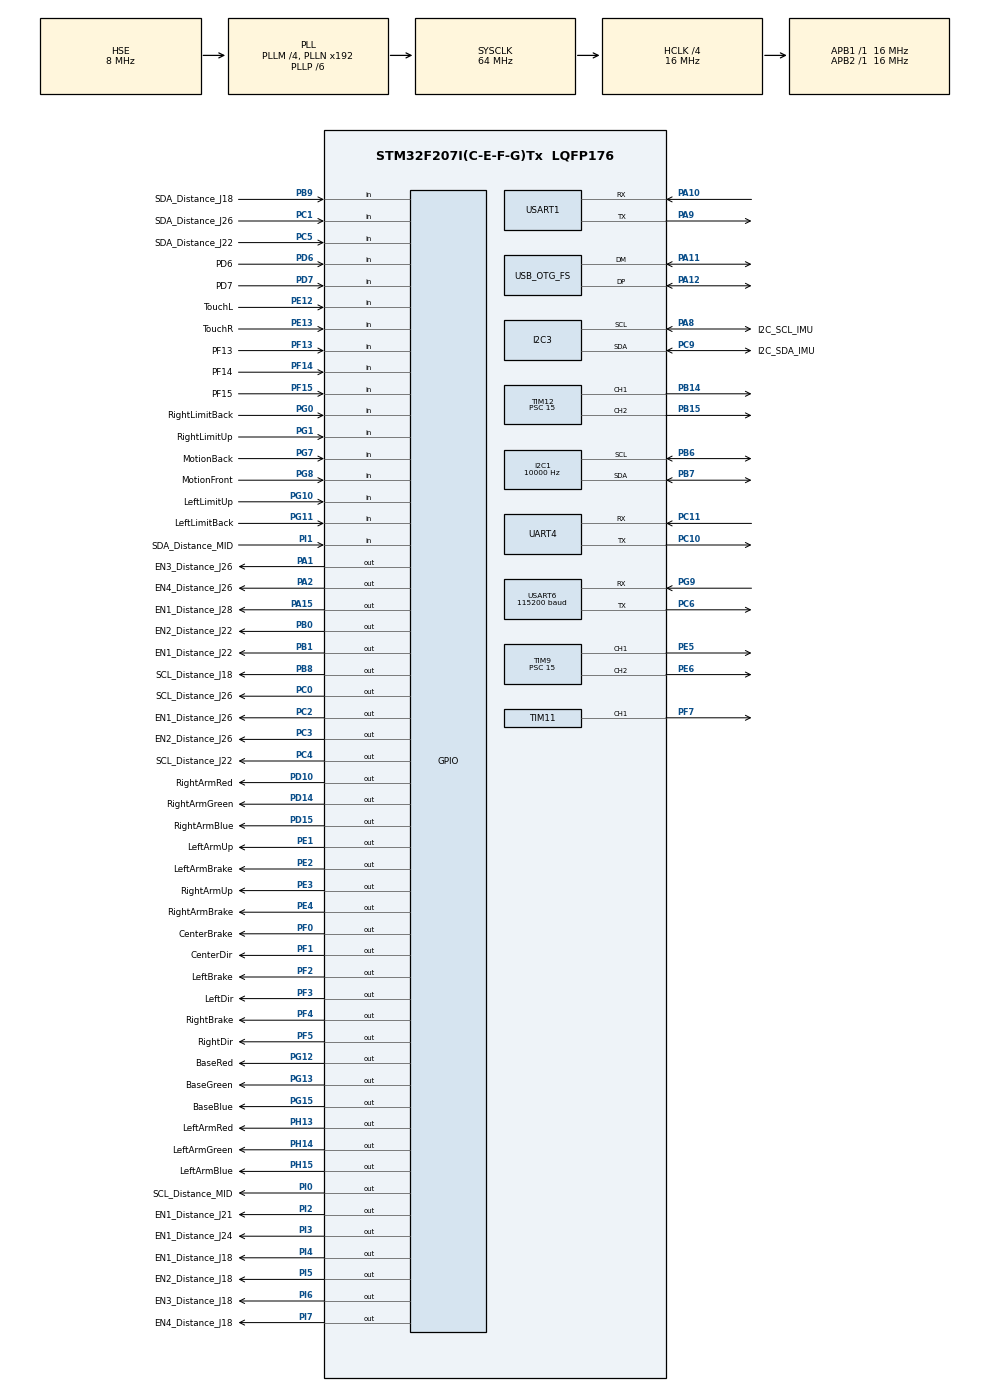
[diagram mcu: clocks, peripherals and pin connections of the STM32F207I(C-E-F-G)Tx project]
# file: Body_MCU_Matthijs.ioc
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Dma.Request0=USART6_RX
Dma.Request1=USART1_RX
Dma.Request2=USART1_TX
Dma.USART1_RX.1.Direction=DMA_PERIPH_TO_MEMORY
Dma.USART1_RX.1.FIFOMode=DMA_FIFOMODE_DISABLE
Dma.USART1_RX.1.Instance=DMA2_Stream2
Dma.USART1_RX.1.MemDataAlignment=DMA_MDATAALIGN_BYTE
Dma.USART1_RX.1.MemInc=DMA_MINC_ENABLE
Dma.USART1_RX.1.Mode=DMA_NORMAL
Dma.USART1_RX.1.PeriphDataAlignment=DMA_PDATAALIGN_BYTE
Dma.USART1_RX.1.PeriphInc=DMA_PINC_DISABLE
Dma.USART1_RX.1.Priority=DMA_PRIORITY_LOW
Dma.USART1_TX.2.Direction=DMA_MEMORY_TO_PERIPH
Dma.USART1_TX.2.FIFOMode=DMA_FIFOMODE_DISABLE
Dma.USART1_TX.2.Instance=DMA2_Stream7
Dma.USART1_TX.2.MemDataAlignment=DMA_MDATAALIGN_BYTE
Dma.USART1_TX.2.MemInc=DMA_MINC_ENABLE
Dma.USART1_TX.2.Mode=DMA_NORMAL
Dma.USART1_TX.2.PeriphDataAlignment=DMA_PDATAALIGN_BYTE
Dma.USART1_TX.2.PeriphInc=DMA_PINC_DISABLE
Dma.USART1_TX.2.Priority=DMA_PRIORITY_LOW
Dma.USART6_RX.0.Direction=DMA_PERIPH_TO_MEMORY
Dma.USART6_RX.0.FIFOMode=DMA_FIFOMODE_DISABLE
Dma.USART6_RX.0.Instance=DMA2_Stream1
Dma.USART6_RX.0.MemDataAlignment=DMA_MDATAALIGN_BYTE
Dma.USART6_RX.0.MemInc=DMA_MINC_ENABLE
Dma.USART6_RX.0.Mode=DMA_NORMAL
Dma.USART6_RX.0.PeriphDataAlignment=DMA_PDATAALIGN_BYTE
Dma.USART6_RX.0.PeriphInc=DMA_PINC_DISABLE
Dma.USART6_RX.0.Priority=DMA_PRIORITY_LOW
I2C1.ClockSpeed=10000
Mcu.Family=STM32F2
Mcu.Name=STM32F207I(C-E-F-G)Tx
Mcu.Package=LQFP176
NVIC.DMA2_Stream1_IRQn=true\:0\:0\:false\:false\:true\:false\:true\:true
NVIC.DMA2_Stream2_IRQn=true\:0\:0\:false\:false\:true\:false\:true\:true
NVIC.DMA2_Stream7_IRQn=true\:0\:0\:false\:false\:true\:false\:true\:true
NVIC.I2C3_EV_IRQn=true\:0\:0\:false\:false\:true\:true\:true\:true
NVIC.OTG_FS_IRQn=true\:0\:0\:false\:false\:true\:false\:true\:true
NVIC.PriorityGroup=NVIC_PRIORITYGROUP_4
NVIC.TIM8_TRG_COM_TIM14_IRQn=true\:0\:0\:false\:false\:true\:true\:true\:true
NVIC.UART4_IRQn=true\:0\:0\:false\:false\:true\:true\:true\:true
NVIC.USART1_IRQn=true\:0\:0\:false\:false\:true\:true\:true\:true
NVIC.USART6_IRQn=true\:0\:0\:false\:false\:true\:true\:true\:true
PA1.GPIO_Label=EN3_Distance_J26
PA1.GPIO_PuPd=GPIO_PULLDOWN
PA1.GPIO_Speed=GPIO_SPEED_FREQ_HIGH
PA1.Signal=GPIO_Output
PA10.Mode=Asynchronous
PA10.Signal=USART1_RX
PA11.Mode=Device_Only
PA11.Signal=USB_OTG_FS_DM
PA12.Mode=Device_Only
PA12.Signal=USB_OTG_FS_DP
PA13.Mode=Serial_Wire
PA13.Signal=SYS_JTMS-SWDIO
PA14.Mode=Serial_Wire
PA14.Signal=SYS_JTCK-SWCLK
PA15.GPIO_Label=EN1_Distance_J28
PA15.GPIO_PuPd=GPIO_PULLDOWN
PA15.GPIO_Speed=GPIO_SPEED_FREQ_HIGH
PA15.Signal=GPIO_Output
PA2.GPIO_Label=EN4_Distance_J26
PA2.GPIO_PuPd=GPIO_PULLDOWN
PA2.GPIO_Speed=GPIO_SPEED_FREQ_HIGH
PA2.Signal=GPIO_Output
PA8.GPIO_Label=I2C_SCL_IMU
PA8.GPIO_Pu=GPIO_PULLUP
PA8.Mode=I2C
PA8.Signal=I2C3_SCL
PA9.Mode=Asynchronous
PA9.Signal=USART1_TX
PB0.GPIO_Label=EN2_Distance_J22
PB0.GPIO_PuPd=GPIO_PULLDOWN
PB0.GPIO_Speed=GPIO_SPEED_FREQ_HIGH
PB0.Signal=GPIO_Output
PB1.GPIO_Label=EN1_Distance_J22
PB1.GPIO_PuPd=GPIO_PULLDOWN
PB1.GPIO_Speed=GPIO_SPEED_FREQ_HIGH
PB1.Signal=GPIO_Output
PB14.GPIO_PuPd=GPIO_PULLDOWN
PB14.Signal=S_TIM12_CH1
PB15.Signal=S_TIM12_CH2
PB6.GPIO_Pu=GPIO_PULLUP
PB6.Mode=I2C
PB6.Signal=I2C1_SCL
PB7.GPIO_Pu=GPIO_PULLUP
PB7.Mode=I2C
PB7.Signal=I2C1_SDA
PB8.GPIO_Label=SCL_Distance_J18
PB8.GPIO_Speed=GPIO_SPEED_FREQ_VERY_HIGH
PB8.Signal=GPIO_Output
PB9.GPIO_Label=SDA_Distance_J18
PB9.GPIO_PuPd=GPIO_PULLUP
PB9.Signal=GPIO_Input
PC0.GPIO_Label=SCL_Distance_J26
PC0.GPIO_PuPd=GPIO_NOPULL
PC0.GPIO_Speed=GPIO_SPEED_FREQ_VERY_HIGH
PC0.Signal=GPIO_Output
PC1.GPIO_Label=SDA_Distance_J26
PC1.GPIO_PuPd=GPIO_PULLUP
PC1.Signal=GPIO_Input
PC10.Mode=Asynchronous
PC10.Signal=UART4_TX
PC11.Mode=Asynchronous
PC11.Signal=UART4_RX
PC2.GPIO_Label=EN1_Distance_J26
PC2.GPIO_PuPd=GPIO_PULLDOWN
PC2.GPIO_Speed=GPIO_SPEED_FREQ_HIGH
PC2.Signal=GPIO_Output
PC3.GPIO_Label=EN2_Distance_J26
PC3.GPIO_PuPd=GPIO_PULLDOWN
PC3.GPIO_Speed=GPIO_SPEED_FREQ_HIGH
PC3.Signal=GPIO_Output
PC4.GPIO_Label=SCL_Distance_J22
PC4.GPIO_Speed=GPIO_SPEED_FREQ_VERY_HIGH
PC4.Signal=GPIO_Output
PC5.GPIO_Label=SDA_Distance_J22
PC5.GPIO_PuPd=GPIO_PULLUP
PC5.Signal=GPIO_Input
PC6.Mode=Asynchronous
PC6.Signal=USART6_TX
PC9.GPIO_Label=I2C_SDA_IMU
PC9.GPIO_Pu=GPIO_PULLUP
PC9.Mode=I2C
PC9.Signal=I2C3_SDA
PD10.GPIO_Label=RightArmRed
PD10.GPIO_PuPd=GPIO_PULLDOWN
PD10.Signal=GPIO_Output
PD14.GPIO_Label=RightArmGreen
PD14.GPIO_PuPd=GPIO_PULLDOWN
PD14.Signal=GPIO_Output
PD15.GPIO_Label=RightArmBlue
PD15.GPIO_PuPd=GPIO_PULLDOWN
PD15.Signal=GPIO_Output
PD6.GPIO_Label=PD6
PD6.Signal=GPIO_Input
PD7.GPIO_Label=PD7
PD7.Signal=GPIO_Input
PE1.GPIO_Label=LeftArmUp
PE1.GPIO_PuPd=GPIO_PULLDOWN
PE1.GPIO_Speed=GPIO_SPEED_FREQ_LOW
PE1.Signal=GPIO_Output
PE12.GPIO_Label=TouchL
PE12.GPIO_PuPd=GPIO_PULLUP
PE12.Signal=GPIO_Input
PE13.GPIO_Label=TouchR
PE13.GPIO_PuPd=GPIO_PULLUP
PE13.Signal=GPIO_Input
PE2.GPIO_Label=LeftArmBrake
PE2.GPIO_PuPd=GPIO_PULLDOWN
PE2.GPIO_Speed=GPIO_SPEED_FREQ_LOW
PE2.Signal=GPIO_Output
PE3.GPIO_Label=RightArmUp
PE3.GPIO_PuPd=GPIO_PULLDOWN
PE3.GPIO_Speed=GPIO_SPEED_FREQ_LOW
PE3.Signal=GPIO_Output
PE4.GPIO_Label=RightArmBrake
PE4.GPIO_PuPd=GPIO_PULLDOWN
PE4.Signal=GPIO_Output
PE5.GPIO_PuPd=GPIO_PULLDOWN
PE5.Signal=S_TIM9_CH1
PE6.GPIO_PuPd=GPIO_PULLDOWN
PE6.Signal=S_TIM9_CH2
PF0.GPIO_Label=CenterBrake
PF0.GPIO_PuPd=GPIO_PULLDOWN
PF0.Signal=GPIO_Output
PF1.GPIO_Label=CenterDir
PF1.GPIO_PuPd=GPIO_PULLDOWN
PF1.Signal=GPIO_Output
PF13.GPIO_Label=PF13
PF13.Signal=GPIO_Input
PF14.GPIO_Label=PF14
PF14.Signal=GPIO_Input
PF15.GPIO_Label=PF15
PF15.Signal=GPIO_Input
PF2.GPIO_Label=LeftBrake
PF2.GPIO_PuPd=GPIO_PULLDOWN
PF2.Signal=GPIO_Output
PF3.GPIO_Label=LeftDir
PF3.GPIO_PuPd=GPIO_PULLDOWN
PF3.Signal=GPIO_Output
PF4.GPIO_Label=RightBrake
PF4.GPIO_PuPd=GPIO_PULLDOWN
PF4.Signal=GPIO_Output
PF5.GPIO_Label=RightDir
PF5.GPIO_PuPd=GPIO_PULLDOWN
PF5.Signal=GPIO_Output
PF7.GPIO_PuPd=GPIO_PULLDOWN
PF7.GPIO_Speed=GPIO_SPEED_FREQ_LOW
PF7.Signal=S_TIM11_CH1
PG0.GPIO_Label=RightLimitBack
PG0.Signal=GPIO_Input
PG1.GPIO_Label=RightLimitUp
PG1.Signal=GPIO_Input
PG10.GPIO_Label=LeftLimitUp
PG10.Signal=GPIO_Input
PG11.GPIO_Label=LeftLimitBack
PG11.Signal=GPIO_Input
PG12.GPIO_Label=BaseRed
PG12.GPIO_PuPd=GPIO_PULLDOWN
PG12.Signal=GPIO_Output
PG13.GPIO_Label=BaseGreen
PG13.GPIO_PuPd=GPIO_PULLDOWN
PG13.Signal=GPIO_Output
PG15.GPIO_Label=BaseBlue
PG15.GPIO_PuPd=GPIO_PULLDOWN
PG15.Signal=GPIO_Output
PG7.GPIO_Label=MotionBack
PG7.Signal=GPIO_Input
PG8.GPIO_Label=MotionFront
PG8.Signal=GPIO_Input
PG9.Mode=Asynchronous
PG9.Signal=USART6_RX
PH0-OSC_IN.Mode=HSE-External-Oscillator
PH0-OSC_IN.Signal=RCC_OSC_IN
PH1-OSC_OUT.Mode=HSE-External-Oscillator
PH1-OSC_OUT.Signal=RCC_OSC_OUT
PH13.GPIO_Label=LeftArmRed
PH13.GPIO_PuPd=GPIO_PULLDOWN
PH13.Signal=GPIO_Output
PH14.GPIO_Label=LeftArmGreen
PH14.GPIO_PuPd=GPIO_PULLDOWN
PH14.Signal=GPIO_Output
PH15.GPIO_Label=LeftArmBlue
PH15.GPIO_PuPd=GPIO_PULLDOWN
PH15.Signal=GPIO_Output
PI0.GPIO_Label=SCL_Distance_MID
PI0.GPIO_Speed=GPIO_SPEED_FREQ_VERY_HIGH
PI0.Signal=GPIO_Output
PI1.GPIO_Label=SDA_Distance_MID
PI1.GPIO_PuPd=GPIO_PULLUP
PI1.Signal=GPIO_Input
PI2.GPIO_Label=EN1_Distance_J21
PI2.GPIO_PuPd=GPIO_PULLDOWN
PI2.GPIO_Speed=GPIO_SPEED_FREQ_HIGH
PI2.Signal=GPIO_Output
PI3.GPIO_Label=EN1_Distance_J24
PI3.GPIO_PuPd=GPIO_PULLDOWN
PI3.GPIO_Speed=GPIO_SPEED_FREQ_HIGH
PI3.Signal=GPIO_Output
PI4.GPIO_Label=EN1_Distance_J18
PI4.GPIO_PuPd=GPIO_PULLDOWN
PI4.GPIO_Speed=GPIO_SPEED_FREQ_HIGH
PI4.Signal=GPIO_Output
PI5.GPIO_Label=EN2_Distance_J18
PI5.GPIO_PuPd=GPIO_PULLDOWN
PI5.GPIO_Speed=GPIO_SPEED_FREQ_HIGH
PI5.Signal=GPIO_Output
PI6.GPIO_Label=EN3_Distance_J18
PI6.GPIO_PuPd=GPIO_PULLDOWN
PI6.GPIO_Speed=GPIO_SPEED_FREQ_HIGH
PI6.Signal=GPIO_Output
PI7.GPIO_Label=EN4_Distance_J18
PI7.GPIO_PuPd=GPIO_PULLDOWN
PI7.GPIO_Speed=GPIO_SPEED_FREQ_HIGH
PI7.Signal=GPIO_Output
ProjectManager.HeapSize=0x200
ProjectManager.StackSize=0x400
ProjectManager.TargetToolchain=STM32CubeIDE
RCC.48MHZClocksFreq_Value=48000000
RCC.AHBCLKDivider=RCC_SYSCLK_DIV4
RCC.AHBFreq_Value=16000000
RCC.APB1Freq_Value=16000000
RCC.APB1TimFreq_Value=16000000
RCC.APB2Freq_Value=16000000
RCC.APB2TimFreq_Value=16000000
RCC.CortexFreq_Value=16000000
RCC.HCLKFreq_Value=16000000
RCC.HSE_VALUE=8000000
RCC.HSI_VALUE=16000000
RCC.LSE_VALUE=32768
RCC.PLLM=4
RCC.PLLP=RCC_PLLP_DIV6
RCC.PLLQ=8
RCC.PLLSourceVirtual=RCC_PLLSOURCE_HSE
RCC.SYSCLKFreq_VALUE=64000000
RCC.SYSCLKSource=RCC_SYSCLKSOURCE_PLLCLK
RCC.VCOOutputFreq_Value=384000000
SH.S_TIM11_CH1.0=TIM11_CH1,PWM Generation1 CH1
SH.S_TIM12_CH1.0=TIM12_CH1,PWM Generation1 CH1
SH.S_TIM12_CH2.0=TIM12_CH2,PWM Generation2 CH2
SH.S_TIM9_CH1.0=TIM9_CH1,PWM Generation1 CH1
SH.S_TIM9_CH2.0=TIM9_CH2,PWM Generation2 CH2
TIM11.AutoReloadPreload=TIM_AUTORELOAD_PRELOAD_ENABLE
TIM11.Channel=TIM_CHANNEL_1
TIM11.Period=100
TIM11.Prescaler=15
TIM12.AutoReloadPreload=TIM_AUTORELOAD_PRELOAD_ENABLE
TIM12.Channel-PWM\ Generation1\ CH1=TIM_CHANNEL_1
TIM12.Channel-PWM\ Generation2\ CH2=TIM_CHANNEL_2
TIM12.Period=100
TIM12.Prescaler=15
TIM14.AutoReloadPreload=TIM_AUTORELOAD_PRELOAD_ENABLE
TIM14.Period=99
TIM14.Prescaler=1599
TIM9.AutoReloadPreload=TIM_AUTORELOAD_PRELOAD_ENABLE
TIM9.Channel-PWM\ Generation1\ CH1=TIM_CHANNEL_1
TIM9.Channel-PWM\ Generation2\ CH2=TIM_CHANNEL_2
TIM9.Period=100
TIM9.Prescaler=15
TIM9.Pulse-PWM\ Generation1\ CH1=0
TIM9.Pulse-PWM\ Generation2\ CH2=0
UART4.VirtualMode=Asynchronous
USART1.VirtualMode=VM_ASYNC
USART6.BaudRate=115200
USART6.VirtualMode=VM_ASYNC
USB_DEVICE.CLASS_NAME_FS=CDC
USB_DEVICE.PID_CDC_FS=14162
USB_DEVICE.PRODUCT_STRING_CDC_FS=Sara Body MCU
USB_DEVICE.USBD_SELF_POWERED-CDC_FS=1
USB_DEVICE.VirtualMode-CDC_FS=Cdc
USB_DEVICE.VirtualModeFS=Cdc_FS
USB_OTG_FS.VirtualMode=Device_Only
VP_TIM11_VS_ClockSourceINT.Mode=Enable_Timer
VP_TIM14_VS_ClockSourceINT.Mode=Enable_Timer
VP_USB_DEVICE_VS_USB_DEVICE_CDC_FS.Mode=CDC_FS
board=custom

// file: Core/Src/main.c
/* USER CODE BEGIN Header */
/**
  ******************************************************************************
  * @file           : main.c
  * @brief          : Main program body
  ******************************************************************************
  * @attention
  *
  * <h2><center>&copy; Copyright (c) 2024 STMicroelectronics.
  * All rights reserved.</center></h2>
  *
  * This software component is licensed by ST under BSD 3-Clause license,
  * the "License"; You may not use this file except in compliance with the
  * License. You may obtain a copy of the License at:
  *                        opensource.org/licenses/BSD-3-Clause
  *
  ******************************************************************************
  */
/* USER CODE END Header */
#include "main.h"
#include "usb_device.h"

/* USER CODE BEGIN Includes */
#include "usbd_cdc_if.h"
#include "protocol_0x55.h"
#include "RGBLeds.h"
#include "RobotGlobals.h"
#include "Arms.h"
#include "Base.h"
#include "MotionSensors.h"
#include "DistanceSensors.h"
#include "Compass.h"
#include "Battery.h"
#include "TouchSensors.h"
#include "stm32f2xx.h"

/* USER CODE END Includes */

I2C_HandleTypeDef hi2c1;
I2C_HandleTypeDef hi2c3;

TIM_HandleTypeDef htim9;
TIM_HandleTypeDef htim11;
TIM_HandleTypeDef htim12;
TIM_HandleTypeDef htim14;

UART_HandleTypeDef huart4;
UART_HandleTypeDef huart1;
UART_HandleTypeDef huart6;
DMA_HandleTypeDef hdma_usart1_rx;
DMA_HandleTypeDef hdma_usart1_tx;
DMA_HandleTypeDef hdma_usart6_rx;

/* USER CODE BEGIN PV */
int Time20Hz = 0;
int Time16Hz = 0;
int Selftest = False;
int TempCS = 0;
int Distance = 0;
char TextBuffer[100];

int Update_25Hz;
int Update_20Hz;
int Update_16Hz;
int Update_10Hz;
int Update_5Hz;
int Update_2Hz;
int Update_1Hz;

int MotionFrontOld = 0;
int MotionFront = 0;
int DemoState[2];

int System_Ready = False;

unsigned int  uart1RxCounter    		= 0;
unsigned char uart1RxChar				= 0;
unsigned char uart4RxChar				= 0;
int datalen = 1;

void BodyStop(void);
void BodyRelease(void);

/* USER CODE END PV */

void SystemClock_Config(void);
static void MX_GPIO_Init(void);
static void MX_DMA_Init(void);
static void MX_TIM14_Init(void);
static void MX_TIM9_Init(void);
static void MX_USART6_UART_Init(void);
static void MX_TIM11_Init(void);
static void MX_TIM12_Init(void);
static void MX_I2C3_Init(void);
static void MX_I2C1_Init(void);
static void MX_USART1_UART_Init(void);
static void MX_UART4_Init(void);

/* USER CODE BEGIN 0 */

//------------------------------------------------------------------------------------
// Uart interrupt callback
// Start 	= 0x55
// Type  	= 0..127 (Command), high bit = response
// Length	= 0..255
// Data
// CRC Low byte
// CRC high byte
// CRC modbus = 0x104B
//------------------------------------------------------------------------------------
//------------------------------------------------------------------------------------
void HAL_UART_RxCpltCallback(UART_HandleTypeDef *huart)
{
	if(huart->Instance == USART6)
	{
		HAL_UART_RxCpltCallback_Encoders(huart);
	}

	if (huart->Instance == USART1)
	{
		Protocol_0x55_NewData((uint8_t*) &uart1RxChar, (uint32_t*) &datalen);
		HAL_UART_Receive_IT(&huart1, &uart1RxChar, 1);	// Enable next character reception
	}

	// To/From Head
	if(huart->Instance == UART4)
	{
		// STOP button pressed
		if (uart4RxChar == 0x01)
		{
			BodyStop();
		}

		// STOP button released
		if (uart4RxChar == 0x02)
		{
			BodyRelease();
		}

		HAL_UART_Receive_IT(&huart4, &uart4RxChar, 1);
	}
}
void BodyStop(void)
{
	RGBLeds_SetAllColors(LeftArm, Red, LED_On);
	RGBLeds_SetAllColors(RightArm, Red, LED_On);
	RGBLeds_SetAllColors(Base, Red, LED_On);

	Base_Abort();
	LeftArm_Abort();
	RightArm_Abort();
}

void BodyRelease(void)
{
	RGBLeds_SetAllColors(LeftArm, Red, LED_Off);
	RGBLeds_SetAllColors(RightArm, Red, LED_Off);
	RGBLeds_SetAllColors(Base, Red, LED_Off);
}

void System_Initialize()
{
	HAL_TIM_Base_Start_IT(&htim14);

	RGBLeds_Init();

	Protocol_0x55_Init(&huart1);

	HAL_UART_Receive_IT(&huart1, &uart1RxChar, 1);
	HAL_UART_Receive_IT(&huart4, &uart4RxChar, 1);

	Encoders_Init(&huart6);

	LeftArm_Init(&htim9);
	RightArm_Init(&htim9);

	LeftArm_Home();
	RightArm_Home();

	Base_Init(&htim9, &htim11, &htim12);

	MotionSensors_Init();
	DistanceSensors_Init();
	TouchSensors_Init();

	Compass_Init(&hi2c3);

	Battery_Init(&hi2c1);
}

void System_Initialze_Update()
{
	if (LeftArm_State.HomeState != Homed) {return;}
	if (RightArm_State.HomeState != Homed) {return;}

	System_Ready = True;
}

void Check_USB_Communication()
{
	if (Protocol_0x55_CheckFifo() > 0)
	{
		int command = Protocol_0x55_GetCommand();

		if (command == CMD_VERSION) 	{ SendVersion();}
		if (command == CMD_LA_COLOR)	{ RGBLeds_SetAllColors(LeftArm, Protocol_0x55_GetData(3), Protocol_0x55_GetData(4));}
		if (command == CMD_RA_COLOR) 	{ RGBLeds_SetAllColors(RightArm, Protocol_0x55_GetData(3), Protocol_0x55_GetData(4));}
		if (command == CMD_BASE_COLOR) 	{ RGBLeds_SetAllColors(Base, Protocol_0x55_GetData(3), Protocol_0x55_GetData(4));}

		if (command == CMD_LARA_COLOR)
		{
			RGBLeds_SetAllColors(LeftArm, Protocol_0x55_GetData(3), Protocol_0x55_GetData(4));
			RGBLeds_SetAllColors(RightArm, Protocol_0x55_GetData(3), Protocol_0x55_GetData(4));
		}

		if (command == CMD_BA_COLOR)
		{
			RGBLeds_SetAllColors(LeftArm, Protocol_0x55_GetData(3), Protocol_0x55_GetData(4));
			RGBLeds_SetAllColors(RightArm, Protocol_0x55_GetData(3), Protocol_0x55_GetData(4));
		}

		if (command == CMD_LA_MOVE) 	{ Generic_Arm_PositionSetpoint(LeftArm, Protocol_0x55_GetData(3), Protocol_0x55_GetData(4));}
		if (command == CMD_RA_MOVE) 	{ Generic_Arm_PositionSetpoint(RightArm, Protocol_0x55_GetData(3), Protocol_0x55_GetData(4));}

		if (command == CMD_BASE_MOVE)
		{
			Base_MotionStartWatchdog(Protocol_0x55_GetData(6));
			Base_VelocitySetpoint(Protocol_0x55_GetData(3), Protocol_0x55_GetData(4), Protocol_0x55_GetData(5));
		}

		if (command == CMD_BASE_BRAKE)
		{
			Base_Brake(Protocol_0x55_GetData(3));
		}

		if (command == CMD_COMP_MOVE)
		{
			Base_MotionStartWatchdog(Protocol_0x55_GetData(5));
			Base_NewCompassRotation(Protocol_0x55_GetData(3), Protocol_0x55_GetData(4));
		}

		if (command == CMD_LA_HOME)
		{
			LeftArm_Home();
		}

		if (command == CMD_RA_HOME)
		{
			RightArm_Home();
		}

		if (command == CMD_BODY_STOP)
		{
			BodyStop();
		}

		Protocol_0x55_MarkProcessed();
	}
}

void TracingUpdate()
{
	memset(TextBuffer, 0x00, 100);

	sprintf(TextBuffer, "%ld\n",(long)(Distance));
	CDC_Transmit_FS((uint8_t*)TextBuffer, strlen(TextBuffer));
}

int ReadMotionFront()
{
	struct MotionSensors_Data_Type *Tmp;
	Tmp = MotionSensors_GetPointer();

	return (Tmp->CurrentValue[0] == 1);
}

int ReadDistancesFrontLeft()
{
	struct Distance_Sensor_Type *Tmp;
	Tmp = DistanceSensors_GetPointer();

	int result = 0;

	for (int i = 2; i < 4; i++)
	{
		if (Tmp->Distance[i] <= 50000) { result = 1;}
	}

	return result;
}

int ReadDistancesFrontRight()
{
	struct Distance_Sensor_Type *Tmp;
	Tmp = DistanceSensors_GetPointer();

	int result = 0;

	for (int i = 4; i < 6; i++)
	{
		if (Tmp->Distance[i] <= 50000) { result = 1;}
	}

	return result;
}

int ReadDistancesLeftMid()
{
	struct Distance_Sensor_Type *Tmp;
	Tmp = DistanceSensors_GetPointer();

	return (Tmp->Distance[9] <= 60000);
}

int ReadDistancesRightMid()
{
	struct Distance_Sensor_Type *Tmp;
	Tmp = DistanceSensors_GetPointer();

	return (Tmp->Distance[10] <= 60000);
}

void RunDemoProgram()
{
	MotionFrontOld = MotionFront;
	MotionFront = ReadMotionFront();

	if (System_Ready == True)
	{
		//-----------------------------------------------------------------------------------
		// Left arm
		//-----------------------------------------------------------------------------------
		if (DemoState[0] == 0)
		{
			if (ReadDistancesLeftMid() || ReadDistancesFrontLeft())
			{
				DemoState[0] = 1;

				RGBLeds_SetAllColors(LeftArm, Blue, LED_Blink_VeryFast);
				Generic_Arm_PositionSetpoint(LeftArm, 1, 150);

				RGBLeds_SetAllColors(Base, Red, LED_Blink_VeryFast);
			}
		}
		else if (DemoState[0] == 1)
		{
			if ((LeftArm_State.MotionState == Motion_Idle) && (ReadDistancesFrontLeft() == 0))
			{
				DemoState[0] = 2;
				RGBLeds_SetAllColors(LeftArm, Green, LED_On);
				RGBLeds_SetAllColors(Base, Blue, LED_On);
				Generic_Arm_PositionSetpoint(LeftArm, 1, 0);
			}
		}
		else if (DemoState[0] == 2)
		{
			if (LeftArm_State.MotionState == Motion_Idle)
			{
				DemoState[0] = 0;
			}
		}

		//-----------------------------------------------------------------------------------
		// Right arm
		//-----------------------------------------------------------------------------------
		if (DemoState[1] == 0)
		{
			if (ReadDistancesRightMid() || ReadDistancesFrontRight())
			{
				DemoState[1] = 1;

				RGBLeds_SetAllColors(RightArm, Blue, LED_Blink_VeryFast);
				RGBLeds_SetAllColors(Base, Blue, LED_Blink_VeryFast);
				Generic_Arm_PositionSetpoint(RightArm, 1, 150);
			}
		}
		else if (DemoState[1] == 1)
		{
			if ((RightArm_State.MotionState == Motion_Idle) && (ReadDistancesFrontRight() == 0))
			{
				DemoState[1] = 2;
				RGBLeds_SetAllColors(RightArm, Green, LED_On);
				RGBLeds_SetAllColors(Base, Blue, LED_On);
				Generic_Arm_PositionSetpoint(RightArm, 1, 0);
			}
		}
		else if (DemoState[1] == 2)
		{
			if (RightArm_State.MotionState == Motion_Idle)
			{
				DemoState[1] = 0;
			}
		}
	}
}

/* USER CODE END 0 */

int main(void)
{

  /* MCU Configuration--------------------------------------------------------*/

  /* Reset of all peripherals, Initializes the Flash interface and the Systick. */
  HAL_Init();

  /* Configure the system clock */
  SystemClock_Config();

  /* Initialize all configured peripherals */
  MX_GPIO_Init();
  MX_DMA_Init();
  MX_TIM14_Init();
  MX_TIM9_Init();
  MX_USART6_UART_Init();
  MX_TIM11_Init();
  MX_TIM12_Init();
  MX_I2C3_Init();
  MX_I2C1_Init();
  MX_USB_DEVICE_Init();
  MX_USART1_UART_Init();
  MX_UART4_Init();
  /* USER CODE BEGIN 2 */

  System_Initialize();

  GenericBase_HAL_Brake(False, LeftBaseMotor);
  GenericBase_HAL_Brake(False, CenterBaseMotor);
  GenericBase_HAL_Brake(False, RightBaseMotor);

  /* USER CODE END 2 */

  /* Infinite loop */
  /* USER CODE BEGIN WHILE */
  while (1)
  {
	  if (Update_25Hz)
	  {
		  Update_25Hz = 0;
		  DistanceSensors_Update();
	  }

	  if (Update_20Hz)
	  {
		  Update_20Hz = 0;
		  Time20Hz += 1;

		  System_Initialze_Update();

		  Base_Update20Hz(Encoders_GetPointer());
		  Arms_Update20Hz(Encoders_GetPointer());
	  }

	  if (Update_10Hz)
	  {
		  Update_10Hz = 0;

		  RGBLeds_Update10Hz();
		  MotionSensors_Update10Hz();

		  Compass_Update();

		  Base_MotionUpdateWatchdog();
		  Base_MotionControl(Compass_GetPointer());

#ifdef DEMO
		  RunDemoProgram();
#endif
	  }

	  if (Update_5Hz)
	  {
		  Update_5Hz = 0;

			TouchSensors_Update();
			if (TouchSensor_AnyChanged()) { SendTouchSensors(TouchSensors_GetPointer());}
	  }

	  if (Update_2Hz)
	  {
		  Update_2Hz = 0;

		  SendEncoders(Encoders_GetPointer());
		  SendCompass(Compass_GetPointer());
	  }

	  if (Update_1Hz)
	  {
		  Update_1Hz = 0;

		  Battery_Update();

		  Compass_Init(&hi2c3);
	  }

	  //--------------------------------------------------------
	  // Limit the check for new data frequency
	  // When run at full speed (no delay), the USB interrupt and the check will lead
	  // to lost bytes. Dont know why and dont know how to solve. But delay works fine.
	  //--------------------------------------------------------
	  Check_USB_Communication();
	  HAL_Delay(1);

    /* USER CODE END WHILE */

  }
}

void SystemClock_Config(void)
{
  RCC_OscInitTypeDef RCC_OscInitStruct = {0};
  RCC_ClkInitTypeDef RCC_ClkInitStruct = {0};

  /** Initializes the RCC Oscillators according to the specified parameters
  * in the RCC_OscInitTypeDef structure.
  */
  RCC_OscInitStruct.OscillatorType = RCC_OSCILLATORTYPE_HSE;
  RCC_OscInitStruct.HSEState = RCC_HSE_ON;
  RCC_OscInitStruct.PLL.PLLState = RCC_PLL_ON;
  RCC_OscInitStruct.PLL.PLLSource = RCC_PLLSOURCE_HSE;
  RCC_OscInitStruct.PLL.PLLM = 4;
  RCC_OscInitStruct.PLL.PLLN = 192;
  RCC_OscInitStruct.PLL.PLLP = RCC_PLLP_DIV6;
  RCC_OscInitStruct.PLL.PLLQ = 8;
  if (HAL_RCC_OscConfig(&RCC_OscInitStruct) != HAL_OK)
  {
    Error_Handler();
  }

  /** Initializes the CPU, AHB and APB buses clocks
  */
  RCC_ClkInitStruct.ClockType = RCC_CLOCKTYPE_HCLK|RCC_CLOCKTYPE_SYSCLK
                              |RCC_CLOCKTYPE_PCLK1|RCC_CLOCKTYPE_PCLK2;
  RCC_ClkInitStruct.SYSCLKSource = RCC_SYSCLKSOURCE_PLLCLK;
  RCC_ClkInitStruct.AHBCLKDivider = RCC_SYSCLK_DIV4;
  RCC_ClkInitStruct.APB1CLKDivider = RCC_HCLK_DIV1;
  RCC_ClkInitStruct.APB2CLKDivider = RCC_HCLK_DIV1;

  if (HAL_RCC_ClockConfig(&RCC_ClkInitStruct, FLASH_LATENCY_0) != HAL_OK)
  {
    Error_Handler();
  }
}

static void MX_I2C1_Init(void)
{

  hi2c1.Instance = I2C1;
  hi2c1.Init.ClockSpeed = 10000;
  hi2c1.Init.DutyCycle = I2C_DUTYCYCLE_2;
  hi2c1.Init.OwnAddress1 = 0;
  hi2c1.Init.AddressingMode = I2C_ADDRESSINGMODE_7BIT;
  hi2c1.Init.DualAddressMode = I2C_DUALADDRESS_DISABLE;
  hi2c1.Init.OwnAddress2 = 0;
  hi2c1.Init.GeneralCallMode = I2C_GENERALCALL_DISABLE;
  hi2c1.Init.NoStretchMode = I2C_NOSTRETCH_DISABLE;
  if (HAL_I2C_Init(&hi2c1) != HAL_OK)
  {
    Error_Handler();
  }

}

static void MX_I2C3_Init(void)
{

  hi2c3.Instance = I2C3;
  hi2c3.Init.ClockSpeed = 100000;
  hi2c3.Init.DutyCycle = I2C_DUTYCYCLE_2;
  hi2c3.Init.OwnAddress1 = 0;
  hi2c3.Init.AddressingMode = I2C_ADDRESSINGMODE_7BIT;
  hi2c3.Init.DualAddressMode = I2C_DUALADDRESS_DISABLE;
  hi2c3.Init.OwnAddress2 = 0;
  hi2c3.Init.GeneralCallMode = I2C_GENERALCALL_DISABLE;
  hi2c3.Init.NoStretchMode = I2C_NOSTRETCH_DISABLE;
  if (HAL_I2C_Init(&hi2c3) != HAL_OK)
  {
    Error_Handler();
  }

}

static void MX_TIM9_Init(void)
{

  TIM_OC_InitTypeDef sConfigOC = {0};

  htim9.Instance = TIM9;
  htim9.Init.Prescaler = 15;
  htim9.Init.CounterMode = TIM_COUNTERMODE_UP;
  htim9.Init.Period = 100;
  htim9.Init.ClockDivision = TIM_CLOCKDIVISION_DIV1;
  htim9.Init.AutoReloadPreload = TIM_AUTORELOAD_PRELOAD_ENABLE;
  if (HAL_TIM_PWM_Init(&htim9) != HAL_OK)
  {
    Error_Handler();
  }
  sConfigOC.OCMode = TIM_OCMODE_PWM1;
  sConfigOC.Pulse = 0;
  sConfigOC.OCPolarity = TIM_OCPOLARITY_HIGH;
  sConfigOC.OCFastMode = TIM_OCFAST_DISABLE;
  if (HAL_TIM_PWM_ConfigChannel(&htim9, &sConfigOC, TIM_CHANNEL_1) != HAL_OK)
  {
    Error_Handler();
  }
  if (HAL_TIM_PWM_ConfigChannel(&htim9, &sConfigOC, TIM_CHANNEL_2) != HAL_OK)
  {
    Error_Handler();
  }
  HAL_TIM_MspPostInit(&htim9);

}

static void MX_TIM11_Init(void)
{

  TIM_OC_InitTypeDef sConfigOC = {0};

  htim11.Instance = TIM11;
  htim11.Init.Prescaler = 15;
  htim11.Init.CounterMode = TIM_COUNTERMODE_UP;
  htim11.Init.Period = 100;
  htim11.Init.ClockDivision = TIM_CLOCKDIVISION_DIV1;
  htim11.Init.AutoReloadPreload = TIM_AUTORELOAD_PRELOAD_ENABLE;
  if (HAL_TIM_Base_Init(&htim11) != HAL_OK)
  {
    Error_Handler();
  }
  if (HAL_TIM_PWM_Init(&htim11) != HAL_OK)
  {
    Error_Handler();
  }
  sConfigOC.OCMode = TIM_OCMODE_PWM1;
  sConfigOC.Pulse = 0;
  sConfigOC.OCPolarity = TIM_OCPOLARITY_HIGH;
  sConfigOC.OCFastMode = TIM_OCFAST_DISABLE;
  if (HAL_TIM_PWM_ConfigChannel(&htim11, &sConfigOC, TIM_CHANNEL_1) != HAL_OK)
  {
    Error_Handler();
  }
  HAL_TIM_MspPostInit(&htim11);

}

static void MX_TIM12_Init(void)
{

  TIM_OC_InitTypeDef sConfigOC = {0};

  htim12.Instance = TIM12;
  htim12.Init.Prescaler = 15;
  htim12.Init.CounterMode = TIM_COUNTERMODE_UP;
  htim12.Init.Period = 100;
  htim12.Init.ClockDivision = TIM_CLOCKDIVISION_DIV1;
  htim12.Init.AutoReloadPreload = TIM_AUTORELOAD_PRELOAD_ENABLE;
  if (HAL_TIM_PWM_Init(&htim12) != HAL_OK)
  {
    Error_Handler();
  }
  sConfigOC.OCMode = TIM_OCMODE_PWM1;
  sConfigOC.Pulse = 0;
  sConfigOC.OCPolarity = TIM_OCPOLARITY_HIGH;
  sConfigOC.OCFastMode = TIM_OCFAST_DISABLE;
  if (HAL_TIM_PWM_ConfigChannel(&htim12, &sConfigOC, TIM_CHANNEL_1) != HAL_OK)
  {
    Error_Handler();
  }
  if (HAL_TIM_PWM_ConfigChannel(&htim12, &sConfigOC, TIM_CHANNEL_2) != HAL_OK)
  {
    Error_Handler();
  }
  HAL_TIM_MspPostInit(&htim12);

}

static void MX_TIM14_Init(void)
{

  htim14.Instance = TIM14;
  htim14.Init.Prescaler = 1599;
  htim14.Init.CounterMode = TIM_COUNTERMODE_UP;
  htim14.Init.Period = 99;
  htim14.Init.ClockDivision = TIM_CLOCKDIVISION_DIV1;
  htim14.Init.AutoReloadPreload = TIM_AUTORELOAD_PRELOAD_ENABLE;
  if (HAL_TIM_Base_Init(&htim14) != HAL_OK)
  {
    Error_Handler();
  }

}

static void MX_UART4_Init(void)
{

  huart4.Instance = UART4;
  huart4.Init.BaudRate = 115200;
  huart4.Init.WordLength = UART_WORDLENGTH_8B;
  huart4.Init.StopBits = UART_STOPBITS_1;
  huart4.Init.Parity = UART_PARITY_NONE;
  huart4.Init.Mode = UART_MODE_TX_RX;
  huart4.Init.HwFlowCtl = UART_HWCONTROL_NONE;
  huart4.Init.OverSampling = UART_OVERSAMPLING_16;
  if (HAL_UART_Init(&huart4) != HAL_OK)
  {
    Error_Handler();
  }

}

static void MX_USART1_UART_Init(void)
{

  huart1.Instance = USART1;
  huart1.Init.BaudRate = 115200;
  huart1.Init.WordLength = UART_WORDLENGTH_8B;
  huart1.Init.StopBits = UART_STOPBITS_1;
  huart1.Init.Parity = UART_PARITY_NONE;
  huart1.Init.Mode = UART_MODE_TX_RX;
  huart1.Init.HwFlowCtl = UART_HWCONTROL_NONE;
  huart1.Init.OverSampling = UART_OVERSAMPLING_16;
  if (HAL_UART_Init(&huart1) != HAL_OK)
  {
    Error_Handler();
  }

}

static void MX_USART6_UART_Init(void)
{

  huart6.Instance = USART6;
  huart6.Init.BaudRate = 115200;
  huart6.Init.WordLength = UART_WORDLENGTH_8B;
  huart6.Init.StopBits = UART_STOPBITS_1;
  huart6.Init.Parity = UART_PARITY_NONE;
  huart6.Init.Mode = UART_MODE_TX_RX;
  huart6.Init.HwFlowCtl = UART_HWCONTROL_NONE;
  huart6.Init.OverSampling = UART_OVERSAMPLING_16;
  if (HAL_UART_Init(&huart6) != HAL_OK)
  {
    Error_Handler();
  }

}

static void MX_DMA_Init(void)
{

  /* DMA controller clock enable */
  __HAL_RCC_DMA2_CLK_ENABLE();

  /* DMA interrupt init */
  /* DMA2_Stream1_IRQn interrupt configuration */
  HAL_NVIC_SetPriority(DMA2_Stream1_IRQn, 0, 0);
  HAL_NVIC_EnableIRQ(DMA2_Stream1_IRQn);
  /* DMA2_Stream2_IRQn interrupt configuration */
  HAL_NVIC_SetPriority(DMA2_Stream2_IRQn, 0, 0);
  HAL_NVIC_EnableIRQ(DMA2_Stream2_IRQn);
  /* DMA2_Stream7_IRQn interrupt configuration */
  HAL_NVIC_SetPriority(DMA2_Stream7_IRQn, 0, 0);
  HAL_NVIC_EnableIRQ(DMA2_Stream7_IRQn);

}

static void MX_GPIO_Init(void)
{
  GPIO_InitTypeDef GPIO_InitStruct = {0};

  /* GPIO Ports Clock Enable */
  __HAL_RCC_GPIOE_CLK_ENABLE();
  __HAL_RCC_GPIOF_CLK_ENABLE();
  __HAL_RCC_GPIOH_CLK_ENABLE();
  __HAL_RCC_GPIOC_CLK_ENABLE();
  __HAL_RCC_GPIOA_CLK_ENABLE();
  __HAL_RCC_GPIOB_CLK_ENABLE();
  __HAL_RCC_GPIOG_CLK_ENABLE();
  __HAL_RCC_GPIOD_CLK_ENABLE();
  __HAL_RCC_GPIOI_CLK_ENABLE();

  /*Configure GPIO pin Output Level */
  HAL_GPIO_WritePin(GPIOE, LeftArmBrake_Pin|RightArmUp_Pin|RightArmBrake_Pin|LeftArmUp_Pin, GPIO_PIN_RESET);

  /*Configure GPIO pin Output Level */
  HAL_GPIO_WritePin(GPIOF, CenterBrake_Pin|CenterDir_Pin|LeftBrake_Pin|LeftDir_Pin
                          |RightBrake_Pin|RightDir_Pin, GPIO_PIN_RESET);

  /*Configure GPIO pin Output Level */
  HAL_GPIO_WritePin(GPIOC, SCL_Distance_J26_Pin|EN1_Distance_J26_Pin|EN2_Distance_J26_Pin|SCL_Distance_J22_Pin, GPIO_PIN_RESET);

  /*Configure GPIO pin Output Level */
  HAL_GPIO_WritePin(GPIOA, EN3_Distance_J26_Pin|EN4_Distance_J26_Pin|EN1_Distance_J28_Pin, GPIO_PIN_RESET);

  /*Configure GPIO pin Output Level */
  HAL_GPIO_WritePin(GPIOB, EN2_Distance_J22_Pin|EN1_Distance_J22_Pin|SCL_Distance_J18_Pin, GPIO_PIN_RESET);

  /*Configure GPIO pin Output Level */
  HAL_GPIO_WritePin(GPIOD, RightArmRed_Pin|RightArmGreen_Pin|RightArmBlue_Pin, GPIO_PIN_RESET);

  /*Configure GPIO pin Output Level */
  HAL_GPIO_WritePin(GPIOH, LeftArmRed_Pin|LeftArmGreen_Pin|LeftArmBlue_Pin, GPIO_PIN_RESET);

  /*Configure GPIO pin Output Level */
  HAL_GPIO_WritePin(GPIOI, SCL_Distance_MID_Pin|EN1_Distance_J21_Pin|EN1_Distance_J24_Pin|EN1_Distance_J18_Pin
                          |EN2_Distance_J18_Pin|EN3_Distance_J18_Pin|EN4_Distance_J18_Pin, GPIO_PIN_RESET);

  /*Configure GPIO pin Output Level */
  HAL_GPIO_WritePin(GPIOG, BaseRed_Pin|BaseGreen_Pin|BaseBlue_Pin, GPIO_PIN_RESET);

  /*Configure GPIO pins : LeftArmBrake_Pin RightArmUp_Pin RightArmBrake_Pin LeftArmUp_Pin */
  GPIO_InitStruct.Pin = LeftArmBrake_Pin|RightArmUp_Pin|RightArmBrake_Pin|LeftArmUp_Pin;
  GPIO_InitStruct.Mode = GPIO_MODE_OUTPUT_PP;
  GPIO_InitStruct.Pull = GPIO_PULLDOWN;
  GPIO_InitStruct.Speed = GPIO_SPEED_FREQ_LOW;
  HAL_GPIO_Init(GPIOE, &GPIO_InitStruct);

  /*Configure GPIO pins : CenterBrake_Pin CenterDir_Pin LeftBrake_Pin LeftDir_Pin
                           RightBrake_Pin RightDir_Pin */
  GPIO_InitStruct.Pin = CenterBrake_Pin|CenterDir_Pin|LeftBrake_Pin|LeftDir_Pin
                          |RightBrake_Pin|RightDir_Pin;
  GPIO_InitStruct.Mode = GPIO_MODE_OUTPUT_PP;
  GPIO_InitStruct.Pull = GPIO_PULLDOWN;
  GPIO_InitStruct.Speed = GPIO_SPEED_FREQ_LOW;
  HAL_GPIO_Init(GPIOF, &GPIO_InitStruct);

  /*Configure GPIO pins : SCL_Distance_J26_Pin SCL_Distance_J22_Pin */
  GPIO_InitStruct.Pin = SCL_Distance_J26_Pin|SCL_Distance_J22_Pin;
  GPIO_InitStruct.Mode = GPIO_MODE_OUTPUT_PP;
  GPIO_InitStruct.Pull = GPIO_NOPULL;
  GPIO_InitStruct.Speed = GPIO_SPEED_FREQ_VERY_HIGH;
  HAL_GPIO_Init(GPIOC, &GPIO_InitStruct);

  /*Configure GPIO pins : SDA_Distance_J26_Pin SDA_Distance_J22_Pin */
  GPIO_InitStruct.Pin = SDA_Distance_J26_Pin|SDA_Distance_J22_Pin;
  GPIO_InitStruct.Mode = GPIO_MODE_INPUT;
  GPIO_InitStruct.Pull = GPIO_PULLUP;
  HAL_GPIO_Init(GPIOC, &GPIO_InitStruct);

  /*Configure GPIO pins : EN1_Distance_J26_Pin EN2_Distance_J26_Pin */
  GPIO_InitStruct.Pin = EN1_Distance_J26_Pin|EN2_Distance_J26_Pin;
  GPIO_InitStruct.Mode = GPIO_MODE_OUTPUT_PP;
  GPIO_InitStruct.Pull = GPIO_PULLDOWN;
  GPIO_InitStruct.Speed = GPIO_SPEED_FREQ_HIGH;
  HAL_GPIO_Init(GPIOC, &GPIO_InitStruct);

  /*Configure GPIO pins : EN3_Distance_J26_Pin EN4_Distance_J26_Pin EN1_Distance_J28_Pin */
  GPIO_InitStruct.Pin = EN3_Distance_J26_Pin|EN4_Distance_J26_Pin|EN1_Distance_J28_Pin;
  GPIO_InitStruct.Mode = GPIO_MODE_OUTPUT_PP;
  GPIO_InitStruct.Pull = GPIO_PULLDOWN;
  GPIO_InitStruct.Speed = GPIO_SPEED_FREQ_HIGH;
  HAL_GPIO_Init(GPIOA, &GPIO_InitStruct);

  /*Configure GPIO pins : EN2_Distance_J22_Pin EN1_Distance_J22_Pin */
  GPIO_InitStruct.Pin = EN2_Distance_J22_Pin|EN1_Distance_J22_Pin;
  GPIO_InitStruct.Mode = GPIO_MODE_OUTPUT_PP;
  GPIO_InitStruct.Pull = GPIO_PULLDOWN;
  GPIO_InitStruct.Speed = GPIO_SPEED_FREQ_HIGH;
  HAL_GPIO_Init(GPIOB, &GPIO_InitStruct);

  /*Configure GPIO pins : PF13_Pin PF14_Pin PF15_Pin */
  GPIO_InitStruct.Pin = PF13_Pin|PF14_Pin|PF15_Pin;
  GPIO_InitStruct.Mode = GPIO_MODE_INPUT;
  GPIO_InitStruct.Pull = GPIO_NOPULL;
  HAL_GPIO_Init(GPIOF, &GPIO_InitStruct);

  /*Configure GPIO pins : RightLimitBack_Pin RightLimitUp_Pin MotionBack_Pin MotionFront_Pin
                           LeftLimitUp_Pin LeftLimitBack_Pin */
  GPIO_InitStruct.Pin = RightLimitBack_Pin|RightLimitUp_Pin|MotionBack_Pin|MotionFront_Pin
                          |LeftLimitUp_Pin|LeftLimitBack_Pin;
  GPIO_InitStruct.Mode = GPIO_MODE_INPUT;
  GPIO_InitStruct.Pull = GPIO_NOPULL;
  HAL_GPIO_Init(GPIOG, &GPIO_InitStruct);

  /*Configure GPIO pins : TouchL_Pin TouchR_Pin */
  GPIO_InitStruct.Pin = TouchL_Pin|TouchR_Pin;
  GPIO_InitStruct.Mode = GPIO_MODE_INPUT;
  GPIO_InitStruct.Pull = GPIO_PULLUP;
  HAL_GPIO_Init(GPIOE, &GPIO_InitStruct);

  /*Configure GPIO pins : RightArmRed_Pin RightArmGreen_Pin RightArmBlue_Pin */
  GPIO_InitStruct.Pin = RightArmRed_Pin|RightArmGreen_Pin|RightArmBlue_Pin;
  GPIO_InitStruct.Mode = GPIO_MODE_OUTPUT_PP;
  GPIO_InitStruct.Pull = GPIO_PULLDOWN;
  GPIO_InitStruct.Speed = GPIO_SPEED_FREQ_LOW;
  HAL_GPIO_Init(GPIOD, &GPIO_InitStruct);

  /*Configure GPIO pins : LeftArmRed_Pin LeftArmGreen_Pin LeftArmBlue_Pin */
  GPIO_InitStruct.Pin = LeftArmRed_Pin|LeftArmGreen_Pin|LeftArmBlue_Pin;
  GPIO_InitStruct.Mode = GPIO_MODE_OUTPUT_PP;
  GPIO_InitStruct.Pull = GPIO_PULLDOWN;
  GPIO_InitStruct.Speed = GPIO_SPEED_FREQ_LOW;
  HAL_GPIO_Init(GPIOH, &GPIO_InitStruct);

  /*Configure GPIO pin : SCL_Distance_MID_Pin */
  GPIO_InitStruct.Pin = SCL_Distance_MID_Pin;
  GPIO_InitStruct.Mode = GPIO_MODE_OUTPUT_PP;
  GPIO_InitStruct.Pull = GPIO_NOPULL;
  GPIO_InitStruct.Speed = GPIO_SPEED_FREQ_VERY_HIGH;
  HAL_GPIO_Init(SCL_Distance_MID_GPIO_Port, &GPIO_InitStruct);

  /*Configure GPIO pin : SDA_Distance_MID_Pin */
  GPIO_InitStruct.Pin = SDA_Distance_MID_Pin;
  GPIO_InitStruct.Mode = GPIO_MODE_INPUT;
  GPIO_InitStruct.Pull = GPIO_PULLUP;
  HAL_GPIO_Init(SDA_Distance_MID_GPIO_Port, &GPIO_InitStruct);

  /*Configure GPIO pins : EN1_Distance_J21_Pin EN1_Distance_J24_Pin EN1_Distance_J18_Pin EN2_Distance_J18_Pin
                           EN3_Distance_J18_Pin EN4_Distance_J18_Pin */
  GPIO_InitStruct.Pin = EN1_Distance_J21_Pin|EN1_Distance_J24_Pin|EN1_Distance_J18_Pin|EN2_Distance_J18_Pin
                          |EN3_Distance_J18_Pin|EN4_Distance_J18_Pin;
  GPIO_InitStruct.Mode = GPIO_MODE_OUTPUT_PP;
  GPIO_InitStruct.Pull = GPIO_PULLDOWN;
  GPIO_InitStruct.Speed = GPIO_SPEED_FREQ_HIGH;
  HAL_GPIO_Init(GPIOI, &GPIO_InitStruct);

  /*Configure GPIO pins : PD6_Pin PD7_Pin */
  GPIO_InitStruct.Pin = PD6_Pin|PD7_Pin;
  GPIO_InitStruct.Mode = GPIO_MODE_INPUT;
  GPIO_InitStruct.Pull = GPIO_NOPULL;
  HAL_GPIO_Init(GPIOD, &GPIO_InitStruct);

  /*Configure GPIO pins : BaseRed_Pin BaseGreen_Pin BaseBlue_Pin */
  GPIO_InitStruct.Pin = BaseRed_Pin|BaseGreen_Pin|BaseBlue_Pin;
  GPIO_InitStruct.Mode = GPIO_MODE_OUTPUT_PP;
  GPIO_InitStruct.Pull = GPIO_PULLDOWN;
  GPIO_InitStruct.Speed = GPIO_SPEED_FREQ_LOW;
  HAL_GPIO_Init(GPIOG, &GPIO_InitStruct);

  /*Configure GPIO pin : SCL_Distance_J18_Pin */
  GPIO_InitStruct.Pin = SCL_Distance_J18_Pin;
  GPIO_InitStruct.Mode = GPIO_MODE_OUTPUT_PP;
  GPIO_InitStruct.Pull = GPIO_NOPULL;
  GPIO_InitStruct.Speed = GPIO_SPEED_FREQ_VERY_HIGH;
  HAL_GPIO_Init(SCL_Distance_J18_GPIO_Port, &GPIO_InitStruct);

  /*Configure GPIO pin : SDA_Distance_J18_Pin */
  GPIO_InitStruct.Pin = SDA_Distance_J18_Pin;
  GPIO_InitStruct.Mode = GPIO_MODE_INPUT;
  GPIO_InitStruct.Pull = GPIO_PULLUP;
  HAL_GPIO_Init(SDA_Distance_J18_GPIO_Port, &GPIO_InitStruct);

}

void Error_Handler(void)
{
  __disable_irq();
  while (1)
  {
  }
}
